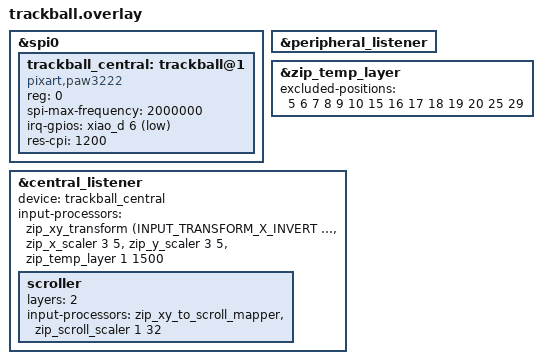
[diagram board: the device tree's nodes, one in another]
&spi0 {
    status = "okay";

    trackball_central: trackball@1 {
        status = "okay";
        compatible = "pixart,paw3222";
        reg = <0>;
        spi-max-frequency = <2000000>;
        irq-gpios = <&xiao_d 6 (GPIO_ACTIVE_LOW | GPIO_PULL_UP)>;
        res-cpi = <1200>;
    };
};

// ペリフェラル（split経由）のリスナーを有効化
&peripheral_listener {
    status = "okay";
};

// excluded-positions以外のキーを押すとAMLが解除される。positionsは、lism.dtsiのpositionsと同じ順番で指定する必要がある。
&zip_temp_layer {
    excluded-positions = <
        5 // y 
        6 // U
        7 // I
        8
        9
        10
        15
        16 // J
        17
        18
        19
        20
        25
        29
    >;
};


// セントラルのリスナーを有効化し、deviceを紐付け
&central_listener {
    status = "okay";
    device = <&trackball_central>;
    input-processors = 
        <&zip_xy_transform (INPUT_TRANSFORM_X_INVERT | INPUT_TRANSFORM_Y_INVERT)>,
        <&zip_x_scaler 3 5>, <&zip_y_scaler 3 5>,
        <&zip_temp_layer 1 1500>;

    scroller {
        layers = <2>;
        input-processors = 
            <&zip_xy_to_scroll_mapper>,
            <&zip_scroll_scaler 1 32>;
    };
};
